# MKL28T7_CORE0 register map
Vendor: Freescale Semiconductor, Inc.; Series: Kinetis_L; File version: 1.6
CPU: CM0PLUS r0p0, little endian, no MPU, no FPU, VTOR, 2 interrupt priority bits
Registers are 32-bit, read-write, reset 0x0 unless marked. A register's access mark holds for its fields unless they carry their own. Offsets are from the block's base; [hi:lo] are bit positions; 'fields as' and 'values as' point back to an identical list.

## RCM — Reset Control Module
Base 0x4007F000; register names take the prefix RCM_
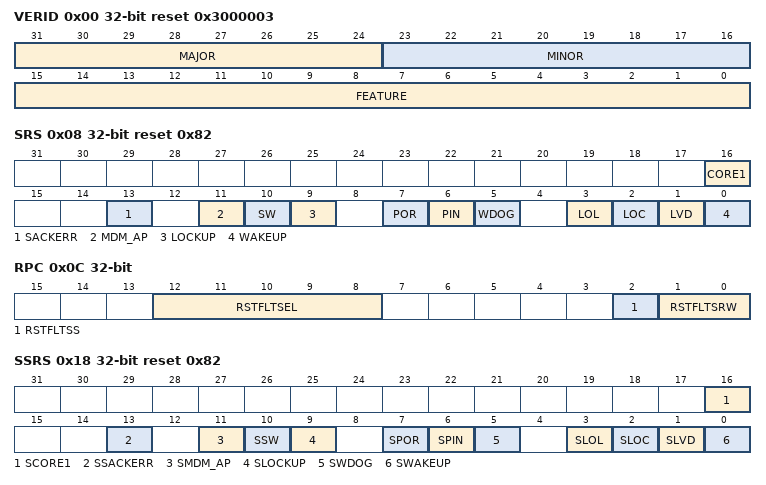
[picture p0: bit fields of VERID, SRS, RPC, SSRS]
0x00 VERID ro reset 0x3000003 — Version ID Register
  [31:24] MAJOR — Major Version Number
  [23:16] MINOR — Minor Version Number
  [15:0] FEATURE — Feature Specification Number
    3=Standard feature set
0x04 PARAM ro reset not defined — Parameter Register
  [31:0] RSTSRC — Reset Source
    0=Reset source not implemented; 1=Reset source implemented
0x08 SRS ro reset 0x82 — System Reset Status Register
  [16] CORE1 — Core 1 Reset
    0=Reset not caused by Core 1 Reset Source; 1=Reset caused by Core 1 Reset Source
  [13] SACKERR — Stop Acknowledge Error
    0=Reset not caused by peripheral failure to acknowledge attempt to enter stop mode; 1=Reset caused by peripheral failure to acknowledge attempt to enter stop mode
  [11] MDM_AP — MDM-AP System Reset Request
    0=Reset was not caused by host debugger system setting of the System Reset Request bit; 1=Reset was caused by host debugger system setting of the System Reset Request bit
  [10] SW — Software
    0=Reset not caused by software setting of SYSRESETREQ bit; 1=Reset caused by software setting of SYSRESETREQ bit
  [9] LOCKUP — Core Lockup
    0=Reset not caused by core LOCKUP event; 1=Reset caused by core LOCKUP event
  [7] POR — Power-On Reset
    0=Reset not caused by POR; 1=Reset caused by POR
  [6] PIN — External Reset Pin
    0=Reset not caused by external reset pin; 1=Reset caused by external reset pin
  [5] WDOG — Watchdog
    0=Reset not caused by watchdog timeout; 1=Reset caused by watchdog timeout
  [3] LOL — Loss-of-Lock Reset
    0=Reset not caused by a loss of lock in the PLL; 1=Reset caused by a loss of lock in the PLL
  [2] LOC — Loss-of-Clock Reset
    0=Reset not caused by a loss of external clock; 1=Reset caused by a loss of external clock
  [1] LVD — Low-Voltage Detect Reset or High-Voltage Detect Reset
    0=Reset not caused by LVD trip, HVD trip or POR; 1=Reset caused by LVD trip, HVD trip or POR
  [0] WAKEUP — VLLS Wakeup Reset
    0=Reset not caused by wakeup from VLLS mode; 1=Reset caused by wakeup from VLLS mode
0x0C RPC — Reset Pin Control register
  [12:8] RSTFLTSEL — Reset Pin Filter Bus Clock Select
  [2] RSTFLTSS — Reset Pin Filter Select in Stop Mode
    0=All filtering disabled; 1=LPO clock filter enabled
  [1:0] RSTFLTSRW — Reset Pin Filter Select in Run and Wait Modes
    0=All filtering disabled; 1=Bus clock filter enabled for normal operation; 2=LPO clock filter enabled for normal operation
0x10 MR — Mode Register
  [2:1] BOOTROM — Boot ROM Configuration
    0=Boot from Flash; 1=Boot from ROM due to BOOTCFG0 pin assertion / Reserved if no Boot pin; 2=Boot form ROM due to FOPT[7] configuration; 3=Boot from ROM due to both BOOTCFG0 pin assertion and FOPT[7] configuration
0x14 FM — Force Mode Register
  [2:1] FORCEROM — Force ROM Boot
    0=No effect; 1=Force boot from ROM with RCM_MR[1] set; 2=Force boot from ROM with RCM_MR[2] set; 3=Force boot from ROM with RCM_MR[2:1] set
0x18 SSRS reset 0x82 — Sticky System Reset Status Register
  [16] SCORE1 — Sticky Core 1 Reset
    values as SRS.CORE1
  [13] SSACKERR — Sticky Stop Acknowledge Error
    values as SRS.SACKERR
  [11] SMDM_AP ro — Sticky MDM-AP System Reset Request
    values as SRS.MDM_AP
  [10] SSW — Sticky Software
    values as SRS.SW
  [9] SLOCKUP — Sticky Core Lockup
    values as SRS.LOCKUP
  [7] SPOR — Sticky Power-On Reset
    0=Reset not caused by POR; 1=Reset caused by POR
  [6] SPIN — Sticky External Reset Pin
    values as SRS.PIN
  [5] SWDOG — Sticky Watchdog
    values as SRS.WDOG
  [3] SLOL — Sticky Loss-of-Lock Reset
    values as SRS.LOL
  [2] SLOC — Sticky Loss-of-Clock Reset
    values as SRS.LOC
  [1] SLVD — Sticky Low-Voltage Detect Reset
    0=Reset not caused by LVD trip or POR; 1=Reset caused by LVD trip or POR
  [0] SWAKEUP — Sticky VLLS Wakeup Reset
    values as SRS.WAKEUP
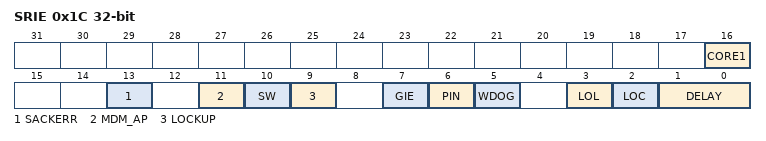
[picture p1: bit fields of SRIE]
0x1C SRIE — System Reset Interrupt Enable Register
  [16] CORE1 — Core 1 Interrupt
    0=Interrupt disabled; 1=Interrupt enabled
  [13] SACKERR — Stop Acknowledge Error Interrupt
    0=Interrupt disabled; 1=Interrupt enabled
  [11] MDM_AP — MDM-AP System Reset Request
    0=Interrupt disabled; 1=Interrupt enabled
  [10] SW — Software Interrupt
    0=Interrupt disabled; 1=Interrupt enabled
  [9] LOCKUP — Core Lockup Interrupt
    0=Interrupt disabled; 1=Interrupt enabled
  [7] GIE — Global Interrupt Enable
    0=All interrupt sources disabled; 1=All interrupt sources enabled
  [6] PIN — External Reset Pin Interrupt
    values as SRS.PIN
  [5] WDOG — Watchdog Interrupt
    0=Interrupt disabled; 1=Interrupt enabled
  [3] LOL — Loss-of-Lock Interrupt
    0=Interrupt disabled; 1=Interrupt enabled
  [2] LOC — Loss-of-Clock Interrupt
    0=Interrupt disabled; 1=Interrupt enabled
  [1:0] DELAY — Reset Delay Time
    0=8 LPO cycles; 1=32 LPO cycles; 2=128 LPO cycles; 3=512 LPO cycles
